# MISC_ANALOG_CTRL register map
Vendor: Texas Instruments
Peripheral module from a debugger description file (folder ucd3138).
Registers are 32-bit, access not given, no defined reset value unless marked. A register's access mark holds for its fields unless they carry their own. Offsets are as the file gives them; lines under a group give offsets from that group; [hi:lo] are bit positions; {n}, {i} and the like mark numbered series; 'fields as' and 'values as' point back to an identical list; <NAME> marks a mode.

## MISCANALOG
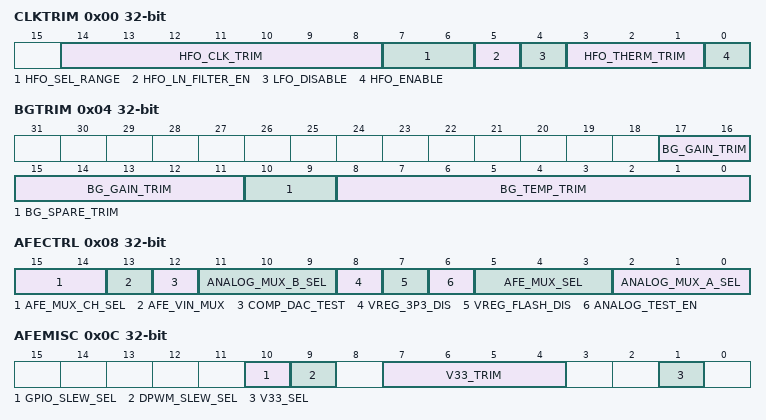
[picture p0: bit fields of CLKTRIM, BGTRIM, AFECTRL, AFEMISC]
0x00 CLKTRIM
  [14:8] HFO_CLK_TRIM rw — HFO Clock Trim
  [7:6] HFO_SEL_RANGE rw — HFO Select Range
  [5] HFO_LN_FILTER_EN rw — HFO Filter Enable
  [4] LFO_DISABLE rw
  [3:1] HFO_THERM_TRIM rw
  [0] HFO_ENABLE rw
0x04 BGTRIM
  [17:11] BG_GAIN_TRIM rw — Bandgap Gain Trim
  [10:9] BG_SPARE_TRIM rw — Bandgap Spare Trim
  [8:0] BG_TEMP_TRIM rw — Bandgap Temp Trim
0x08 AFECTRL
  [15:14] AFE_MUX_CH_SEL rw — AFE Mux Channel Select
  [13] AFE_VIN_MUX rw — Isolation Buffer Selection Test
  [12] COMP_DAC_TEST rw — Comparator DAC Test
  [11:9] ANALOG_MUX_B_SEL rw — Analog Mux B Select
  [8] VREG_3P3_DIS rw — 3.3V Regulator Disable
  [7] VREG_FLASH_DIS rw — 2.6V Regulator Disable
  [6] ANALOG_TEST_EN rw — Enable Analog Test Points
  [5:3] AFE_MUX_SEL rw — Analog Front End Mux Select
  [2:0] ANALOG_MUX_A_SEL rw — Analog Mux A Select
0x0C AFEMISC
  [10] GPIO_SLEW_SEL rw — GPIO Slew Select
  [9] DPWM_SLEW_SEL rw — DPWM pin Slew Select
  [7:4] V33_TRIM rw — V33 Trim Bits
  [1] V33_SEL rw — Selects V33 Reference
0x10 PKGID
  [1:0] PKG_ID rw — Package ID
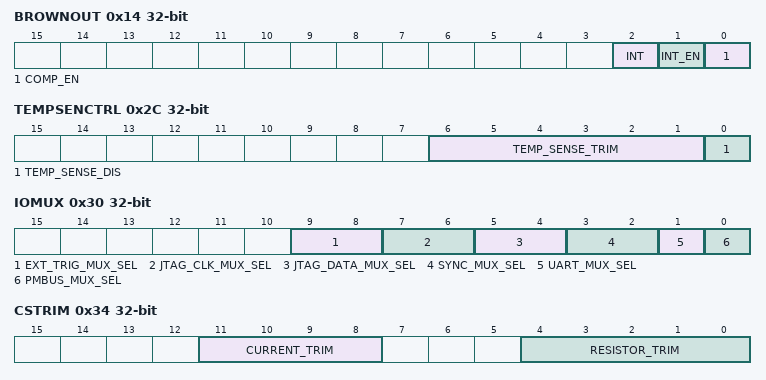
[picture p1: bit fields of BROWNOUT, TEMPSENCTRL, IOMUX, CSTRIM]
0x14 BROWNOUT
  [2] INT ro — Brownout Interrupt Latched Status
  [1] INT_EN rw — Brownout Interrupt Enable
  [0] COMP_EN rw — Brownout Enable
0x18 GLBIOEN
  [29:0] GLOBAL_IO_EN rw — Global I/O Enable
0x1C GLBIOOE
  [29:0] GLOBAL_IO_OE rw — Global I/O Output Enable
0x20 GLBIOOD
  [29:0] GLOBAL_IO_OD rw — Global I/O Open Drain Enable
0x24 GLBIOVAL
  [29:0] GLOBAL_IO_VALUE rw
0x28 GLBIOREAD
  [29:0] GLOBAL_IO_READ ro — Global I/O Value
0x2C TEMPSENCTRL
  [6:1] TEMP_SENSE_TRIM rw — Temperature Sensor Trim
  [0] TEMP_SENSE_DIS rw — Temperature Sensor Disable
0x30 IOMUX
  [9:8] EXT_TRIG_MUX_SEL rw — EXT TRIG Pins Mux Control
  [7:6] JTAG_CLK_MUX_SEL rw — JTAG Data Pins Mux Control
  [5:4] JTAG_DATA_MUX_SEL rw — JTAG Data Pins Mux Control
  [3:2] SYNC_MUX_SEL rw — SYNC Pins Mux Control
  [1] UART_MUX_SEL rw — UART Pins Mux Control
  [0] PMBUS_MUX_SEL rw — PMBus Pins Mux Control
0x34 CSTRIM
  [11:8] CURRENT_TRIM rw — Current Sharing Current Trim
  [4:0] RESISTOR_TRIM rw — Current Sharing Resistor Trim
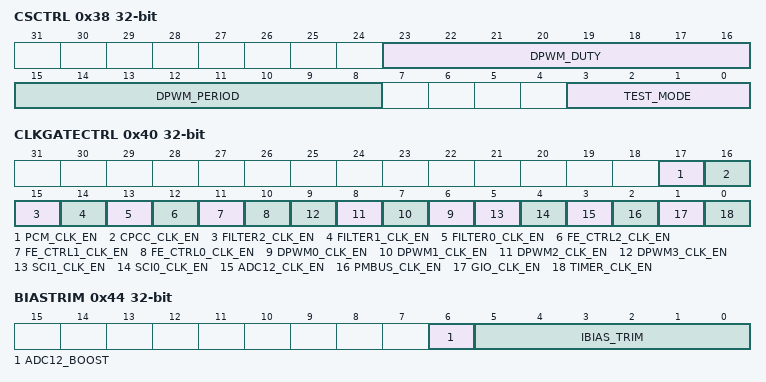
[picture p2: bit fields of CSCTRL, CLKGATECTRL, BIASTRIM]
0x38 CSCTRL
  [23:16] DPWM_DUTY rw — DPWM Duty/Pulse Width for Cur Share
  [15:8] DPWM_PERIOD rw — DPWM Period for Current Share
  [3:0] TEST_MODE rw — Current Sharing Test Mode
0x3C TEMPREF
  [11:0] TEMP_REF rw — Temperature Reference
0x40 CLKGATECTRL
  [17] PCM_CLK_EN rw — Peak Current Mode Clock Enable
  [16] CPCC_CLK_EN rw — Constant Power/Constant Current Clock Enable
  [15] FILTER2_CLK_EN rw — Filter 2 Clock Enable
  [14] FILTER1_CLK_EN rw — Filter 1 Clock Enable
  [13] FILTER0_CLK_EN rw — Filter 0 Clock Enable
  [12] FE_CTRL2_CLK_EN rw — Front End Control 2 Clock Enable
  [11] FE_CTRL1_CLK_EN rw — Front End Control 2 Clock Enable
  [10] FE_CTRL0_CLK_EN rw — Front End Control 2 Clock Enable
  [n+6] DPWM{n}_CLK_EN rw (n=0..3) — DPWM4 Clock Enable
  [5] SCI1_CLK_EN rw — SCI1 Clock Enable
  [4] SCI0_CLK_EN rw — SCI0 Clock Enable
  [3] ADC12_CLK_EN rw — ADC12 Control Clock Enable
  [2] PMBUS_CLK_EN rw — PMBus I/F Clock Enable
  [1] GIO_CLK_EN rw — GIO Clock Enable
  [0] TIMER_CLK_EN rw — Timer Clock Enable
0x44 BIASTRIM
  [6] ADC12_BOOST rw
  [5:0] IBIAS_TRIM rw — IBias Trim Bits
